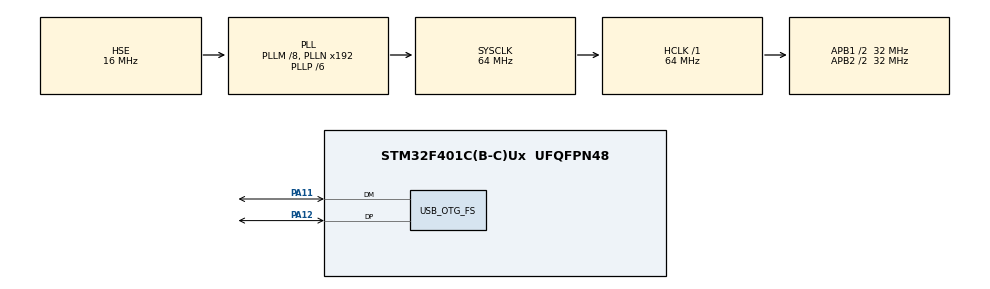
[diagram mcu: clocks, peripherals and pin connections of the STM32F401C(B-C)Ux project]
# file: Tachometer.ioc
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Mcu.Family=STM32F4
Mcu.Name=STM32F401C(B-C)Ux
Mcu.Package=UFQFPN48
NVIC.OTG_FS_IRQn=true\:0\:0\:false\:false\:true\:false\:true\:true
NVIC.PriorityGroup=NVIC_PRIORITYGROUP_4
NVIC.TIM2_IRQn=true\:0\:0\:false\:false\:true\:true\:true\:true
NVIC.TIM5_IRQn=true\:0\:0\:false\:false\:true\:true\:true\:true
PA11.Mode=Device_Only
PA11.Signal=USB_OTG_FS_DM
PA12.Mode=Device_Only
PA12.Signal=USB_OTG_FS_DP
PA13.Mode=Serial_Wire
PA13.Signal=SYS_JTMS-SWDIO
PA14.Mode=Serial_Wire
PA14.Signal=SYS_JTCK-SWCLK
PH0\ -\ OSC_IN.Mode=HSE-External-Oscillator
PH0\ -\ OSC_IN.Signal=RCC_OSC_IN
PH1\ -\ OSC_OUT.Mode=HSE-External-Oscillator
PH1\ -\ OSC_OUT.Signal=RCC_OSC_OUT
ProjectManager.HeapSize=0x200
ProjectManager.StackSize=0x400
ProjectManager.TargetToolchain=Makefile
RCC.48MHZClocksFreq_Value=48000000
RCC.AHBFreq_Value=64000000
RCC.APB1CLKDivider=RCC_HCLK_DIV2
RCC.APB1Freq_Value=32000000
RCC.APB1TimFreq_Value=64000000
RCC.APB2CLKDivider=RCC_HCLK_DIV2
RCC.APB2Freq_Value=32000000
RCC.APB2TimFreq_Value=64000000
RCC.CortexFreq_Value=64000000
RCC.HCLKFreq_Value=64000000
RCC.HSE_VALUE=16000000
RCC.HSI_VALUE=16000000
RCC.LSE_VALUE=32768
RCC.PLLM=8
RCC.PLLP=RCC_PLLP_DIV6
RCC.PLLQ=8
RCC.SYSCLKFreq_VALUE=64000000
RCC.SYSCLKSource=RCC_SYSCLKSOURCE_PLLCLK
RCC.VCOOutputFreq_Value=384000000
TIM2.Prescaler=63
TIM5.Period=99999
TIM5.Prescaler=63
USB_DEVICE.CLASS_NAME_FS=CDC
USB_DEVICE.VirtualMode=Cdc
USB_DEVICE.VirtualModeFS=Cdc_FS
USB_OTG_FS.VirtualMode=Device_Only
VP_IWDG_VS_IWDG.Mode=IWDG_Activate
VP_TIM2_VS_ClockSourceINT.Mode=Internal
VP_TIM5_VS_ClockSourceINT.Mode=Internal
VP_USB_DEVICE_VS_USB_DEVICE_CDC_FS.Mode=CDC_FS
board=custom

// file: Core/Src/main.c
/* USER CODE BEGIN Header */
/**
  ******************************************************************************
  * @file           : main.c
  * @brief          : Main program body
  ******************************************************************************
  * @attention
  *
  * Copyright (c) 2023 STMicroelectronics.
  * All rights reserved.
  *
  * This software is licensed under terms that can be found in the LICENSE file
  * in the root directory of this software component.
  * If no LICENSE file comes with this software, it is provided AS-IS.
  *
  ******************************************************************************
  */
/* USER CODE END Header */
#include "main.h"
#include "usb_device.h"

/* USER CODE BEGIN Includes */
#include "CAProtocolStm.h"
#include "tachometer.h"
/* USER CODE END Includes */

IWDG_HandleTypeDef hiwdg;

TIM_HandleTypeDef htim2;
TIM_HandleTypeDef htim5;

void SystemClock_Config(void);
static void MX_GPIO_Init(void);
static void MX_TIM2_Init(void);
static void MX_TIM5_Init(void);
static void MX_IWDG_Init(void);

int main(void)
{

  /* MCU Configuration--------------------------------------------------------*/

  /* Reset of all peripherals, Initializes the Flash interface and the Systick. */
  HAL_Init();

  /* Configure the system clock */
  SystemClock_Config();

  /* USER CODE BEGIN SysInit */
  const char* bootMsg = CAonBoot();
  /* USER CODE END SysInit */

  /* Initialize all configured peripherals */
  MX_GPIO_Init();
  MX_TIM2_Init();
  MX_USB_DEVICE_Init();
  MX_TIM5_Init();
  MX_IWDG_Init();
  /* USER CODE BEGIN 2 */
  tachoInputInit(&htim2, &htim5);
  /* USER CODE END 2 */

  /* Infinite loop */
  /* USER CODE BEGIN WHILE */
  while (1)
  {
    tachoInputLoop(bootMsg);
    HAL_IWDG_Refresh(&hiwdg);
    /* USER CODE END WHILE */

  }
}

void SystemClock_Config(void)
{
  RCC_OscInitTypeDef RCC_OscInitStruct = {0};
  RCC_ClkInitTypeDef RCC_ClkInitStruct = {0};

  /** Configure the main internal regulator output voltage
  */
  __HAL_RCC_PWR_CLK_ENABLE();
  __HAL_PWR_VOLTAGESCALING_CONFIG(PWR_REGULATOR_VOLTAGE_SCALE2);

  /** Initializes the RCC Oscillators according to the specified parameters
  * in the RCC_OscInitTypeDef structure.
  */
  RCC_OscInitStruct.OscillatorType = RCC_OSCILLATORTYPE_LSI|RCC_OSCILLATORTYPE_HSE;
  RCC_OscInitStruct.HSEState = RCC_HSE_ON;
  RCC_OscInitStruct.LSIState = RCC_LSI_ON;
  RCC_OscInitStruct.PLL.PLLState = RCC_PLL_ON;
  RCC_OscInitStruct.PLL.PLLSource = RCC_PLLSOURCE_HSE;
  RCC_OscInitStruct.PLL.PLLM = 8;
  RCC_OscInitStruct.PLL.PLLN = 192;
  RCC_OscInitStruct.PLL.PLLP = RCC_PLLP_DIV6;
  RCC_OscInitStruct.PLL.PLLQ = 8;
  if (HAL_RCC_OscConfig(&RCC_OscInitStruct) != HAL_OK)
  {
    Error_Handler();
  }

  /** Initializes the CPU, AHB and APB buses clocks
  */
  RCC_ClkInitStruct.ClockType = RCC_CLOCKTYPE_HCLK|RCC_CLOCKTYPE_SYSCLK
                              |RCC_CLOCKTYPE_PCLK1|RCC_CLOCKTYPE_PCLK2;
  RCC_ClkInitStruct.SYSCLKSource = RCC_SYSCLKSOURCE_PLLCLK;
  RCC_ClkInitStruct.AHBCLKDivider = RCC_SYSCLK_DIV1;
  RCC_ClkInitStruct.APB1CLKDivider = RCC_HCLK_DIV2;
  RCC_ClkInitStruct.APB2CLKDivider = RCC_HCLK_DIV2;

  if (HAL_RCC_ClockConfig(&RCC_ClkInitStruct, FLASH_LATENCY_2) != HAL_OK)
  {
    Error_Handler();
  }
}

static void MX_IWDG_Init(void)
{

  hiwdg.Instance = IWDG;
  hiwdg.Init.Prescaler = IWDG_PRESCALER_4;
  hiwdg.Init.Reload = 4095;
  if (HAL_IWDG_Init(&hiwdg) != HAL_OK)
  {
    Error_Handler();
  }

}

static void MX_TIM2_Init(void)
{

  TIM_ClockConfigTypeDef sClockSourceConfig = {0};
  TIM_MasterConfigTypeDef sMasterConfig = {0};

  htim2.Instance = TIM2;
  htim2.Init.Prescaler = 63;
  htim2.Init.CounterMode = TIM_COUNTERMODE_UP;
  htim2.Init.Period = 4294967295;
  htim2.Init.ClockDivision = TIM_CLOCKDIVISION_DIV1;
  htim2.Init.AutoReloadPreload = TIM_AUTORELOAD_PRELOAD_DISABLE;
  if (HAL_TIM_Base_Init(&htim2) != HAL_OK)
  {
    Error_Handler();
  }
  sClockSourceConfig.ClockSource = TIM_CLOCKSOURCE_INTERNAL;
  if (HAL_TIM_ConfigClockSource(&htim2, &sClockSourceConfig) != HAL_OK)
  {
    Error_Handler();
  }
  sMasterConfig.MasterOutputTrigger = TIM_TRGO_RESET;
  sMasterConfig.MasterSlaveMode = TIM_MASTERSLAVEMODE_DISABLE;
  if (HAL_TIMEx_MasterConfigSynchronization(&htim2, &sMasterConfig) != HAL_OK)
  {
    Error_Handler();
  }

}

static void MX_TIM5_Init(void)
{

  TIM_ClockConfigTypeDef sClockSourceConfig = {0};
  TIM_MasterConfigTypeDef sMasterConfig = {0};

  htim5.Instance = TIM5;
  htim5.Init.Prescaler = 63;
  htim5.Init.CounterMode = TIM_COUNTERMODE_UP;
  htim5.Init.Period = 99999;
  htim5.Init.ClockDivision = TIM_CLOCKDIVISION_DIV1;
  htim5.Init.AutoReloadPreload = TIM_AUTORELOAD_PRELOAD_DISABLE;
  if (HAL_TIM_Base_Init(&htim5) != HAL_OK)
  {
    Error_Handler();
  }
  sClockSourceConfig.ClockSource = TIM_CLOCKSOURCE_INTERNAL;
  if (HAL_TIM_ConfigClockSource(&htim5, &sClockSourceConfig) != HAL_OK)
  {
    Error_Handler();
  }
  sMasterConfig.MasterOutputTrigger = TIM_TRGO_RESET;
  sMasterConfig.MasterSlaveMode = TIM_MASTERSLAVEMODE_DISABLE;
  if (HAL_TIMEx_MasterConfigSynchronization(&htim5, &sMasterConfig) != HAL_OK)
  {
    Error_Handler();
  }

}

static void MX_GPIO_Init(void)
{

  /* GPIO Ports Clock Enable */
  __HAL_RCC_GPIOH_CLK_ENABLE();
  __HAL_RCC_GPIOA_CLK_ENABLE();

}

void Error_Handler(void)
{
  __disable_irq();
  while (1)
  {
  }
}
